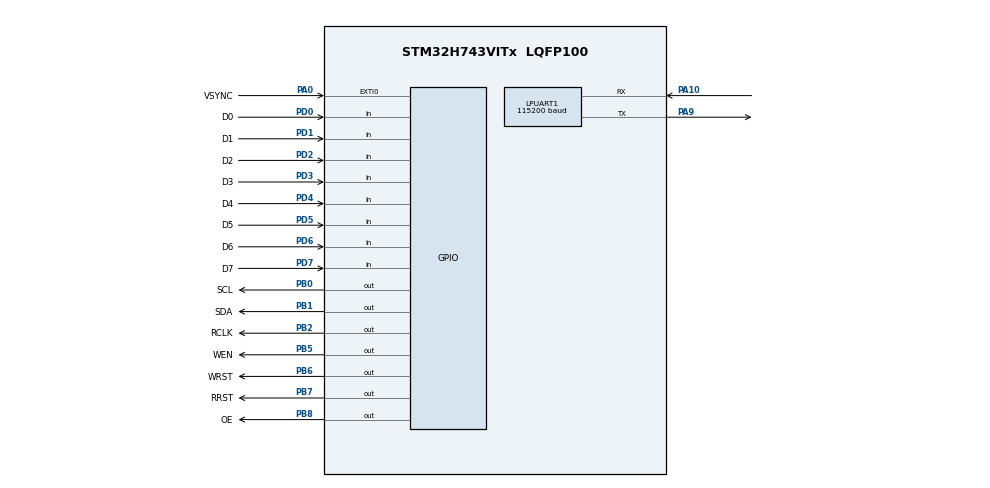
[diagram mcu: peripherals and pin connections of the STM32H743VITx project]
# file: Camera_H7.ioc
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CORTEX_M7.CPU_DCache=Enabled
CORTEX_M7.CPU_ICache=Enabled
LPUART1.BaudRate=115200
Mcu.Family=STM32H7
Mcu.Name=STM32H743VITx
Mcu.Package=LQFP100
NVIC.EXTI0_IRQn=true\:0\:0\:false\:false\:true\:true\:true
NVIC.LPUART1_IRQn=true\:0\:0\:false\:false\:true\:true\:true
NVIC.PriorityGroup=NVIC_PRIORITYGROUP_4
PA0.GPIO_Label=VSYNC
PA0.Signal=GPXTI0
PA10.GPIO_Speed=GPIO_SPEED_FREQ_VERY_HIGH
PA10.Mode=Asynchronous
PA10.Signal=LPUART1_RX
PA9.GPIO_Speed=GPIO_SPEED_FREQ_VERY_HIGH
PA9.Mode=Asynchronous
PA9.Signal=LPUART1_TX
PB0.GPIO_Label=SCL
PB0.GPIO_Speed=GPIO_SPEED_FREQ_VERY_HIGH
PB0.Signal=GPIO_Output
PB1.GPIO_Label=SDA
PB1.GPIO_Speed=GPIO_SPEED_FREQ_VERY_HIGH
PB1.Signal=GPIO_Output
PB2.GPIO_Label=RCLK
PB2.GPIO_Speed=GPIO_SPEED_FREQ_VERY_HIGH
PB2.Signal=GPIO_Output
PB5.GPIO_Label=WEN
PB5.GPIO_Speed=GPIO_SPEED_FREQ_VERY_HIGH
PB5.Signal=GPIO_Output
PB6.GPIO_Label=WRST
PB6.GPIO_Speed=GPIO_SPEED_FREQ_VERY_HIGH
PB6.Signal=GPIO_Output
PB7.GPIO_Label=RRST
PB7.GPIO_Speed=GPIO_SPEED_FREQ_VERY_HIGH
PB7.Signal=GPIO_Output
PB8.GPIO_Label=OE
PB8.GPIO_Speed=GPIO_SPEED_FREQ_VERY_HIGH
PB8.Signal=GPIO_Output
PD0.GPIO_Label=D0
PD0.GPIO_PuPd=GPIO_PULLUP
PD0.Signal=GPIO_Input
PD1.GPIO_Label=D1
PD1.GPIO_PuPd=GPIO_PULLUP
PD1.Signal=GPIO_Input
PD2.GPIO_Label=D2
PD2.GPIO_PuPd=GPIO_PULLUP
PD2.Signal=GPIO_Input
PD3.GPIO_Label=D3
PD3.GPIO_PuPd=GPIO_PULLUP
PD3.Signal=GPIO_Input
PD4.GPIO_Label=D4
PD4.GPIO_PuPd=GPIO_PULLUP
PD4.Signal=GPIO_Input
PD5.GPIO_Label=D5
PD5.GPIO_PuPd=GPIO_PULLUP
PD5.Signal=GPIO_Input
PD6.GPIO_Label=D6
PD6.GPIO_PuPd=GPIO_PULLUP
PD6.Signal=GPIO_Input
PD7.GPIO_Label=D7
PD7.GPIO_PuPd=GPIO_PULLUP
PD7.Signal=GPIO_Input
ProjectManager.HeapSize=0x1000
ProjectManager.StackSize=0x2000
ProjectManager.TargetToolchain=SW4STM32
RCC.ADCFreq_Value=129000000
RCC.APB1Freq_Value=120000000
RCC.APB2Freq_Value=120000000
RCC.APB3Freq_Value=120000000
RCC.APB4Freq_Value=120000000
RCC.CortexFreq_Value=480000000
RCC.D1PPRE=RCC_APB3_DIV2
RCC.D2PPRE1=RCC_APB1_DIV2
RCC.D2PPRE2=RCC_APB2_DIV2
RCC.D3PPRE=RCC_APB4_DIV2
RCC.DIVM1=4
RCC.DIVN1=60
RCC.HCLKFreq_Value=240000000
RCC.HPRE=RCC_HCLK_DIV2
RCC.PLL2FRACN=0
RCC.PLL3FRACN=0
RCC.PLLFRACN=0
RCC.PWR_Regulator_Voltage_Scale=PWR_REGULATOR_VOLTAGE_SCALE0
RCC.SYSCLKFreq_VALUE=480000000
RCC.SYSCLKSource=RCC_SYSCLKSOURCE_PLLCLK
RCC.USBFreq_Value=480000000
board=custom

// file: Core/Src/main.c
/* USER CODE BEGIN Header */
/**
  ******************************************************************************
  * @file           : main.c
  * @brief          : Main program body
  ******************************************************************************
  * @attention
  *
  * <h2><center>&copy; Copyright (c) 2021 STMicroelectronics.
  * All rights reserved.</center></h2>
  *
  * This software component is licensed by ST under BSD 3-Clause license,
  * the "License"; You may not use this file except in compliance with the
  * License. You may obtain a copy of the License at:
  *                        opensource.org/licenses/BSD-3-Clause
  *
  ******************************************************************************
  */
/* USER CODE END Header */
#include "main.h"
/* USER CODE BEGIN Includes */
#include "delay.h"
#include <stdio.h>
#include "SCCB.h"
#include "OV7725.h"
/* USER CODE END Includes */

UART_HandleTypeDef hlpuart1;

void SystemClock_Config(void);
static void MX_GPIO_Init(void);
static void MX_LPUART1_UART_Init(void);

int main(void)
{

  /* Enable I-Cache---------------------------------------------------------*/
  SCB_EnableICache();

  /* Enable D-Cache---------------------------------------------------------*/
  SCB_EnableDCache();

  /* MCU Configuration--------------------------------------------------------*/

  /* Reset of all peripherals, Initializes the Flash interface and the Systick. */
  HAL_Init();

  /* USER CODE BEGIN Init */
    HAL_Delay(1);
  /* USER CODE END Init */

  /* Configure the system clock */
  SystemClock_Config();

  /* Initialize all configured peripherals */
  MX_GPIO_Init();
  MX_LPUART1_UART_Init();
  /* USER CODE BEGIN 2 */
SCCB_Init();
OV7725_Init();

  /* USER CODE END 2 */

  /* Infinite loop */
  while (1)
  {

  }
}

void SystemClock_Config(void)
{
  RCC_OscInitTypeDef RCC_OscInitStruct = {0};
  RCC_ClkInitTypeDef RCC_ClkInitStruct = {0};

  /** Supply configuration update enable
  */
  HAL_PWREx_ConfigSupply(PWR_LDO_SUPPLY);
  /** Configure the main internal regulator output voltage
  */
  __HAL_PWR_VOLTAGESCALING_CONFIG(PWR_REGULATOR_VOLTAGE_SCALE0);

  while(!__HAL_PWR_GET_FLAG(PWR_FLAG_VOSRDY)) {}
  /** Initializes the RCC Oscillators according to the specified parameters
  * in the RCC_OscInitTypeDef structure.
  */
  RCC_OscInitStruct.OscillatorType = RCC_OSCILLATORTYPE_HSI;
  RCC_OscInitStruct.HSIState = RCC_HSI_DIV1;
  RCC_OscInitStruct.HSICalibrationValue = RCC_HSICALIBRATION_DEFAULT;
  RCC_OscInitStruct.PLL.PLLState = RCC_PLL_ON;
  RCC_OscInitStruct.PLL.PLLSource = RCC_PLLSOURCE_HSI;
  RCC_OscInitStruct.PLL.PLLM = 4;
  RCC_OscInitStruct.PLL.PLLN = 60;
  RCC_OscInitStruct.PLL.PLLP = 2;
  RCC_OscInitStruct.PLL.PLLQ = 2;
  RCC_OscInitStruct.PLL.PLLR = 2;
  RCC_OscInitStruct.PLL.PLLRGE = RCC_PLL1VCIRANGE_3;
  RCC_OscInitStruct.PLL.PLLVCOSEL = RCC_PLL1VCOWIDE;
  RCC_OscInitStruct.PLL.PLLFRACN = 0;
  if (HAL_RCC_OscConfig(&RCC_OscInitStruct) != HAL_OK)
  {
    Error_Handler();
  }
  /** Initializes the CPU, AHB and APB buses clocks
  */
  RCC_ClkInitStruct.ClockType = RCC_CLOCKTYPE_HCLK|RCC_CLOCKTYPE_SYSCLK
                              |RCC_CLOCKTYPE_PCLK1|RCC_CLOCKTYPE_PCLK2
                              |RCC_CLOCKTYPE_D3PCLK1|RCC_CLOCKTYPE_D1PCLK1;
  RCC_ClkInitStruct.SYSCLKSource = RCC_SYSCLKSOURCE_PLLCLK;
  RCC_ClkInitStruct.SYSCLKDivider = RCC_SYSCLK_DIV1;
  RCC_ClkInitStruct.AHBCLKDivider = RCC_HCLK_DIV2;
  RCC_ClkInitStruct.APB3CLKDivider = RCC_APB3_DIV2;
  RCC_ClkInitStruct.APB1CLKDivider = RCC_APB1_DIV2;
  RCC_ClkInitStruct.APB2CLKDivider = RCC_APB2_DIV2;
  RCC_ClkInitStruct.APB4CLKDivider = RCC_APB4_DIV2;

  if (HAL_RCC_ClockConfig(&RCC_ClkInitStruct, FLASH_LATENCY_4) != HAL_OK)
  {
    Error_Handler();
  }
}

static void MX_LPUART1_UART_Init(void)
{

  hlpuart1.Instance = LPUART1;
  hlpuart1.Init.BaudRate = 115200;
  hlpuart1.Init.WordLength = UART_WORDLENGTH_8B;
  hlpuart1.Init.StopBits = UART_STOPBITS_1;
  hlpuart1.Init.Parity = UART_PARITY_NONE;
  hlpuart1.Init.Mode = UART_MODE_TX_RX;
  hlpuart1.Init.HwFlowCtl = UART_HWCONTROL_NONE;
  hlpuart1.Init.OneBitSampling = UART_ONE_BIT_SAMPLE_DISABLE;
  hlpuart1.Init.ClockPrescaler = UART_PRESCALER_DIV1;
  hlpuart1.AdvancedInit.AdvFeatureInit = UART_ADVFEATURE_NO_INIT;
  hlpuart1.FifoMode = UART_FIFOMODE_DISABLE;
  if (HAL_UART_Init(&hlpuart1) != HAL_OK)
  {
    Error_Handler();
  }
  if (HAL_UARTEx_SetTxFifoThreshold(&hlpuart1, UART_TXFIFO_THRESHOLD_1_8) != HAL_OK)
  {
    Error_Handler();
  }
  if (HAL_UARTEx_SetRxFifoThreshold(&hlpuart1, UART_RXFIFO_THRESHOLD_1_8) != HAL_OK)
  {
    Error_Handler();
  }
  if (HAL_UARTEx_DisableFifoMode(&hlpuart1) != HAL_OK)
  {
    Error_Handler();
  }

}

static void MX_GPIO_Init(void)
{
  GPIO_InitTypeDef GPIO_InitStruct = {0};

  /* GPIO Ports Clock Enable */
  __HAL_RCC_GPIOA_CLK_ENABLE();
  __HAL_RCC_GPIOB_CLK_ENABLE();
  __HAL_RCC_GPIOD_CLK_ENABLE();

  /*Configure GPIO pin Output Level */
  HAL_GPIO_WritePin(GPIOB, SCL_Pin|SDA_Pin|RCLK_Pin|WEN_Pin
                          |WRST_Pin|RRST_Pin|OE_Pin, GPIO_PIN_RESET);

  /*Configure GPIO pin : VSYNC_Pin */
  GPIO_InitStruct.Pin = VSYNC_Pin;
  GPIO_InitStruct.Mode = GPIO_MODE_IT_RISING;
  GPIO_InitStruct.Pull = GPIO_NOPULL;
  HAL_GPIO_Init(VSYNC_GPIO_Port, &GPIO_InitStruct);

  /*Configure GPIO pins : SCL_Pin SDA_Pin RCLK_Pin WEN_Pin
                           WRST_Pin RRST_Pin OE_Pin */
  GPIO_InitStruct.Pin = SCL_Pin|SDA_Pin|RCLK_Pin|WEN_Pin
                          |WRST_Pin|RRST_Pin|OE_Pin;
  GPIO_InitStruct.Mode = GPIO_MODE_OUTPUT_PP;
  GPIO_InitStruct.Pull = GPIO_NOPULL;
  GPIO_InitStruct.Speed = GPIO_SPEED_FREQ_VERY_HIGH;
  HAL_GPIO_Init(GPIOB, &GPIO_InitStruct);

  /*Configure GPIO pins : D0_Pin D1_Pin D2_Pin D3_Pin
                           D4_Pin D5_Pin D6_Pin D7_Pin */
  GPIO_InitStruct.Pin = D0_Pin|D1_Pin|D2_Pin|D3_Pin
                          |D4_Pin|D5_Pin|D6_Pin|D7_Pin;
  GPIO_InitStruct.Mode = GPIO_MODE_INPUT;
  GPIO_InitStruct.Pull = GPIO_PULLUP;
  HAL_GPIO_Init(GPIOD, &GPIO_InitStruct);

  /* EXTI interrupt init*/
  HAL_NVIC_SetPriority(EXTI0_IRQn, 0, 0);
  HAL_NVIC_EnableIRQ(EXTI0_IRQn);

}

void Error_Handler(void)
{
  __disable_irq();
  while (1)
  {
  }
}

/************************ (C) COPYRIGHT STMicroelectronics *****END OF FILE****/
